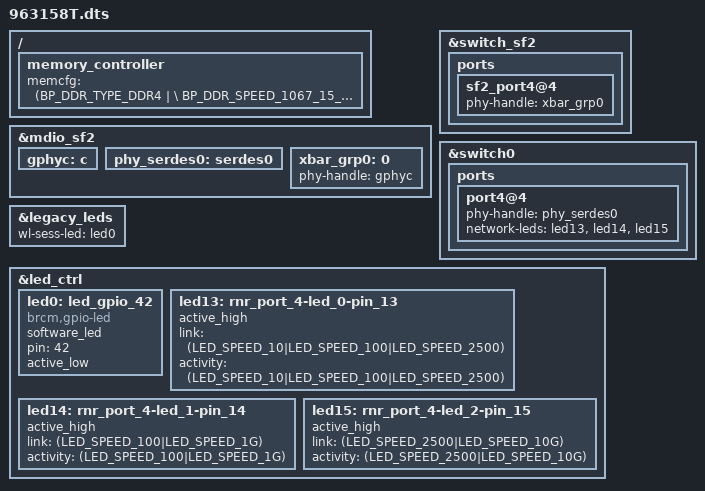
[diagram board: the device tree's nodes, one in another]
#include "63158.dtsi"

/ {
	memory_controller {
		memcfg = <(BP_DDR_TYPE_DDR4 | \
			BP_DDR_SPEED_1067_15_15_15 | \
			BP_DDR_TOTAL_SIZE_4096MB   | \
			BP_DDR_DEVICE_WIDTH_8      | \
			BP_DDR_TOTAL_WIDTH_32BIT   | \
			BP_DDR_SSC_CONFIG_1)>;
	};
};
&mdio_sf2 {

	/* PHYs connected to crossbar */
	gphyc:c {
		status = "okay";
	};

	/* PHY directly connected to Runner */
	phy_serdes0:serdes0 {
		status = "okay";
	};

	/* Crossbar groups */
	xbar_grp0:0 {
		phy-handle = <&gphyc>;
		status = "okay";
	};
};

&switch_sf2 {
	ports {

		sf2_port4@4 {
			phy-handle = <&xbar_grp0>;
			/* wrong GPHY4 LED in board design */
			status = "okay";
		};
	};
};

&switch0 {
	ports {
		
		port4@4 {
			phy-handle = <&phy_serdes0>;
			network-leds = <&led13 &led14 &led15>;			
			status = "okay";
		};
	};
};

&legacy_leds {
	wl-sess-led = <&led0>;	
};

&led_ctrl {
	led0:led_gpio_42 {
		compatible = "brcm,gpio-led";
		software_led;
		pin = <42>;
		active_low;
	};

	led13: rnr_port_4-led_0-pin_13 {
		active_high;
		link = <(LED_SPEED_10|LED_SPEED_100|LED_SPEED_2500)>;
		activity = <(LED_SPEED_10|LED_SPEED_100|LED_SPEED_2500)>;
		status = "okay";
	};
	led14: rnr_port_4-led_1-pin_14 {
		active_high;
		link = <(LED_SPEED_100|LED_SPEED_1G)>;
		activity = <(LED_SPEED_100|LED_SPEED_1G)>;
		status = "okay";
	};
	led15: rnr_port_4-led_2-pin_15 {
		active_high;
		link = <(LED_SPEED_2500|LED_SPEED_10G)>;
		activity = <(LED_SPEED_2500|LED_SPEED_10G)>;
		status = "okay";
	};
};
